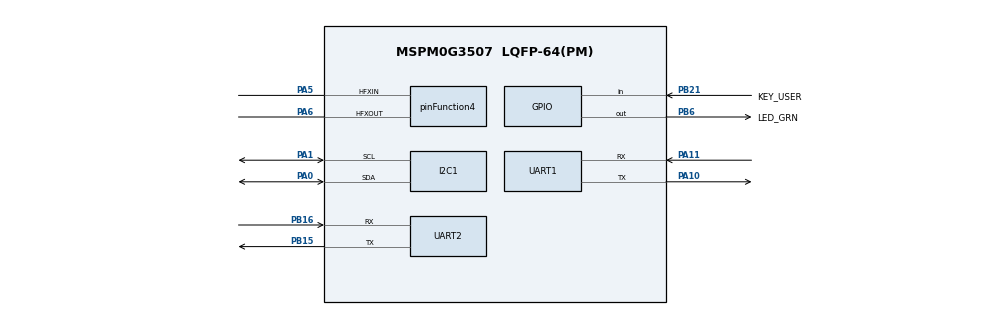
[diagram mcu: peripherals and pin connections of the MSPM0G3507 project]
/**
 * AI AGENTS: Do not edit this file directly. There is no validation or error feedback when
 * editing manually — mistakes will be silent until the file is loaded in SysConfig.
 * Use the SysConfig MCP server instead to make changes with immediate error reporting.
 *
 * These arguments were used when this file was generated. They will be automatically applied on subsequent loads
 * via the GUI or CLI. Run CLI with '--help' for additional information on how to override these arguments.
 * @cliArgs --device "MSPM0G350X" --part "Default" --package "LQFP-64(PM)" --product "mspm0_sdk@2.10.00.04"
 * @v2CliArgs --device "MSPM0G3507" --package "LQFP-64(PM)" --product "mspm0_sdk@2.10.00.04"
 * @versions {"tool":"1.28.0+4712"}
 */

/**
 * Import the modules used in this configuration.
 */
const GPIO          = scripting.addModule("/ti/driverlib/GPIO", {}, false);
const GPIO1         = GPIO.addInstance();
const GPIO2         = GPIO.addInstance();
const I2C           = scripting.addModule("/ti/driverlib/I2C", {}, false);
const I2C1          = I2C.addInstance();
const UART          = scripting.addModule("/ti/driverlib/UART", {}, false);
const UART1         = UART.addInstance();
const UART2         = UART.addInstance();
const SYSCTL        = scripting.addModule("/ti/driverlib/SYSCTL");
const SYSTICK       = scripting.addModule("/ti/driverlib/SYSTICK");
const ProjectConfig = scripting.addModule("/ti/project_config/ProjectConfig");

/**
 * Write custom configuration values to the imported modules.
 */
const divider9       = system.clockTree["UDIV"];
divider9.divideValue = 2;

const mux2       = system.clockTree["CANCLKMUX"];
mux2.inputSelect = "CANCLKMUX_PLLCLK1_OUT";

const mux4       = system.clockTree["EXHFMUX"];
mux4.inputSelect = "EXHFMUX_XTAL";

const mux8       = system.clockTree["HSCLKMUX"];
mux8.inputSelect = "HSCLKMUX_SYSPLL2X";

const mux10       = system.clockTree["MFPCLKMUX"];
mux10.inputSelect = "MFPCLKMUX_HFCLK";

const mux12       = system.clockTree["SYSPLLMUX"];
mux12.inputSelect = "zSYSPLLMUX_HFCLK";

const pinFunction4                        = system.clockTree["HFXT"];
pinFunction4.inputFreq                    = 40;
pinFunction4.enable                       = true;
pinFunction4.HFXTStartup                  = 10;
pinFunction4.HFCLKMonitor                 = true;
pinFunction4.peripheral.hfxInPin.$assign  = "PA5";
pinFunction4.peripheral.hfxOutPin.$assign = "PA6";

GPIO1.port                           = "PORTB";
GPIO1.$name                          = "GPIO_GRP_LEDS";
GPIO1.portSegment                    = "Lower";
GPIO1.associatedPins.create(2);
GPIO1.associatedPins[0].$name        = "LED_GRN";
GPIO1.associatedPins[0].initialValue = "SET";
GPIO1.associatedPins[0].ioStructure  = "SD";
GPIO1.associatedPins[0].assignedPin  = "6";
GPIO1.associatedPins[0].pin.$assign  = "PB6";
GPIO1.associatedPins[1].$name        = "LED_RED";
GPIO1.associatedPins[1].initialValue = "SET";
GPIO1.associatedPins[1].ioStructure  = "SD";
GPIO1.associatedPins[1].assignedPin  = "7";

const Board = scripting.addModule("/ti/driverlib/Board", {}, false);

GPIO2.port                          = "PORTB";
GPIO2.$name                         = "GPIO_GRP_KEY";
GPIO2.portSegment                   = "Upper";
GPIO2.associatedPins[0].$name       = "KEY_USER";
GPIO2.associatedPins[0].direction   = "INPUT";
GPIO2.associatedPins[0].interruptEn = true;
GPIO2.associatedPins[0].polarity    = "RISE_FALL";
GPIO2.associatedPins[0].assignedPin = "21";
GPIO2.associatedPins[0].pin.$assign = "PB21";

I2C1.$name                     = "I2C_TEMP";
I2C1.basicEnableController     = true;
I2C1.basicControllerBusSpeed   = 100000;
I2C1.advControllerTXFIFOTRIG   = "BYTES_1";
I2C1.intController             = ["ARBITRATION_LOST", "NACK", "RXFIFO_TRIGGER", "RX_DONE", "TX_DONE"];
I2C1.peripheral.$assign        = "I2C0";
I2C1.peripheral.sdaPin.$assign = "PA0";
I2C1.peripheral.sclPin.$assign = "PA1";

UART1.$name                  = "UART_TYPEC";
UART1.enableFIFO             = true;
UART1.enableDMARX            = true;
UART1.enableDMATX            = true;
UART1.targetBaudRate         = 115200;
UART1.enableInternalLoopback = false;
UART1.enabledInterrupts      = ["DMA_DONE_RX", "DMA_DONE_TX"];
UART1.enabledDMARXTriggers   = "DL_UART_DMA_INTERRUPT_RX";
UART1.enabledDMATXTriggers   = "DL_UART_DMA_INTERRUPT_TX";
UART1.rxFifoThreshold        = "DL_UART_RX_FIFO_LEVEL_ONE_ENTRY";
UART1.peripheral.$assign     = "UART0";
UART1.peripheral.txPin.$assign = "PA10";
UART1.peripheral.rxPin.$assign = "PA11";
UART1.DMA_CHANNEL_TX.$name              = "DMA_TYPEC_TX";
UART1.DMA_CHANNEL_TX.addressMode        = "b2f";
UART1.DMA_CHANNEL_TX.srcIncDec          = "INCREMENT";
UART1.DMA_CHANNEL_TX.srcLength          = "BYTE";
UART1.DMA_CHANNEL_TX.dstLength          = "BYTE";
UART1.DMA_CHANNEL_TX.peripheral.$assign = "DMA_CH0";
UART1.DMA_CHANNEL_RX.$name              = "DMA_TYPEC_RX";
UART1.DMA_CHANNEL_RX.addressMode        = "f2b";
UART1.DMA_CHANNEL_RX.dstIncDec          = "INCREMENT";
UART1.DMA_CHANNEL_RX.srcLength          = "BYTE";
UART1.DMA_CHANNEL_RX.dstLength          = "BYTE";
UART1.DMA_CHANNEL_RX.peripheral.$assign = "DMA_CH1";

UART2.$name                  = "UART_EXTERNAL";
UART2.enableFIFO             = true;
UART2.enableDMARX            = true;
UART2.enableDMATX            = true;
UART2.targetBaudRate         = 115200;
UART2.enableInternalLoopback = false;
UART2.enabledInterrupts      = ["DMA_DONE_RX", "DMA_DONE_TX"];
UART2.enabledDMARXTriggers   = "DL_UART_DMA_INTERRUPT_RX";
UART2.enabledDMATXTriggers   = "DL_UART_DMA_INTERRUPT_TX";
UART2.rxFifoThreshold        = "DL_UART_RX_FIFO_LEVEL_ONE_ENTRY";
UART2.peripheral.$assign     = "UART2";
UART2.peripheral.txPin.$assign = "PB15";
UART2.peripheral.rxPin.$assign = "PB16";
UART2.DMA_CHANNEL_TX.$name              = "DMA_EXTERNAL_TX";
UART2.DMA_CHANNEL_TX.addressMode        = "b2f";
UART2.DMA_CHANNEL_TX.srcIncDec          = "INCREMENT";
UART2.DMA_CHANNEL_TX.srcLength          = "BYTE";
UART2.DMA_CHANNEL_TX.dstLength          = "BYTE";
UART2.DMA_CHANNEL_TX.peripheral.$assign = "DMA_CH2";
UART2.DMA_CHANNEL_RX.$name              = "DMA_EXTERNAL_RX";
UART2.DMA_CHANNEL_RX.addressMode        = "f2b";
UART2.DMA_CHANNEL_RX.dstIncDec          = "INCREMENT";
UART2.DMA_CHANNEL_RX.srcLength          = "BYTE";
UART2.DMA_CHANNEL_RX.dstLength          = "BYTE";
UART2.DMA_CHANNEL_RX.peripheral.$assign = "DMA_CH3";

SYSCTL.clockTreeEn           = true;
SYSCTL.forceDefaultClkConfig = true;
SYSCTL.validateClkStatus     = true;

SYSTICK.periodEnable    = true;
SYSTICK.period          = 80000;
SYSTICK.interruptEnable = true;
SYSTICK.systickEnable   = true;

ProjectConfig.genLibCMSIS = true;
ProjectConfig.compiler    = "gcc";

/**
 * Pinmux solution for unlocked pins/peripherals. This ensures that minor changes to the automatic solver in a future
 * version of the tool will not impact the pinmux you originally saw.  These lines can be completely deleted in order to
 * re-solve from scratch.
 */
pinFunction4.peripheral.$suggestSolution     = "SYSCTL";
GPIO1.associatedPins[1].pin.$suggestSolution = "PB7";
Board.peripheral.$suggestSolution            = "DEBUGSS";
Board.peripheral.swclkPin.$suggestSolution   = "PA20";
Board.peripheral.swdioPin.$suggestSolution   = "PA19";
